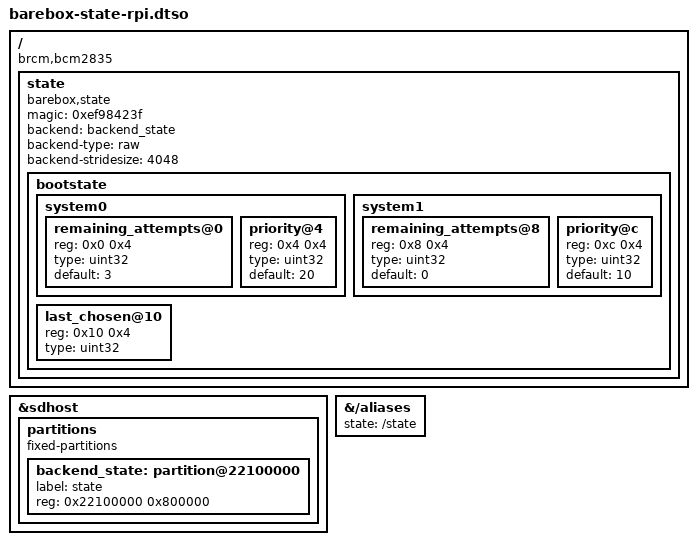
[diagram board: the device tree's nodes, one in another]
/dts-v1/;
/plugin/;

/ {
	compatible = "brcm,bcm2835", "brcm,bcm2708", "brcm,bcm2709";

	fragment@0 {
		target = <&sdhost>;
		__overlay__ {
			status = "okay";
			partitions {
				#address-cells = <1>;
				#size-cells = <1>;
				compatible = "fixed-partitions";

				backend_state: partition@22100000 {
					label = "state";
					reg = <0x22100000 0x800000>;
				};
			};
		};
	};


	fragment@1 {
		target-path = "/";
		__overlay__ {
			state: state {
				#address-cells = <1>;
				#size-cells = <1>;
				magic = <0xef98423f>;
				compatible = "barebox,state";
				backend = <&backend_state>;
				backend-type = "raw";
				backend-stridesize = <4048>;

				bootstate {
					#address-cells = <1>;
					#size-cells = <1>;

					system0 {
						#address-cells = <1>;
						#size-cells = <1>;
						remaining_attempts@0 {
							reg = <0x0 0x4>;
							type = "uint32";
							default = <3>;
						};
						priority@4 {
							reg = <0x4 0x4>;
							type = "uint32";
							default = <20>;
						};
					};
					system1 {
						#address-cells = <1>;
						#size-cells = <1>;
						remaining_attempts@8 {
							reg = <0x8 0x4>;
							type = "uint32";
							default = <0>;
						};
						priority@c {
							reg = <0xc 0x4>;
							type = "uint32";
							default = <10>;
						};
					};
					last_chosen@10 {
						reg = <0x10 0x4>;
						type = "uint32";
					};
				};
			};
		};
	};

	fragment@3 {
		target-path = "/aliases";
		__overlay__ {
			state = "/state";
		};
	};
};

